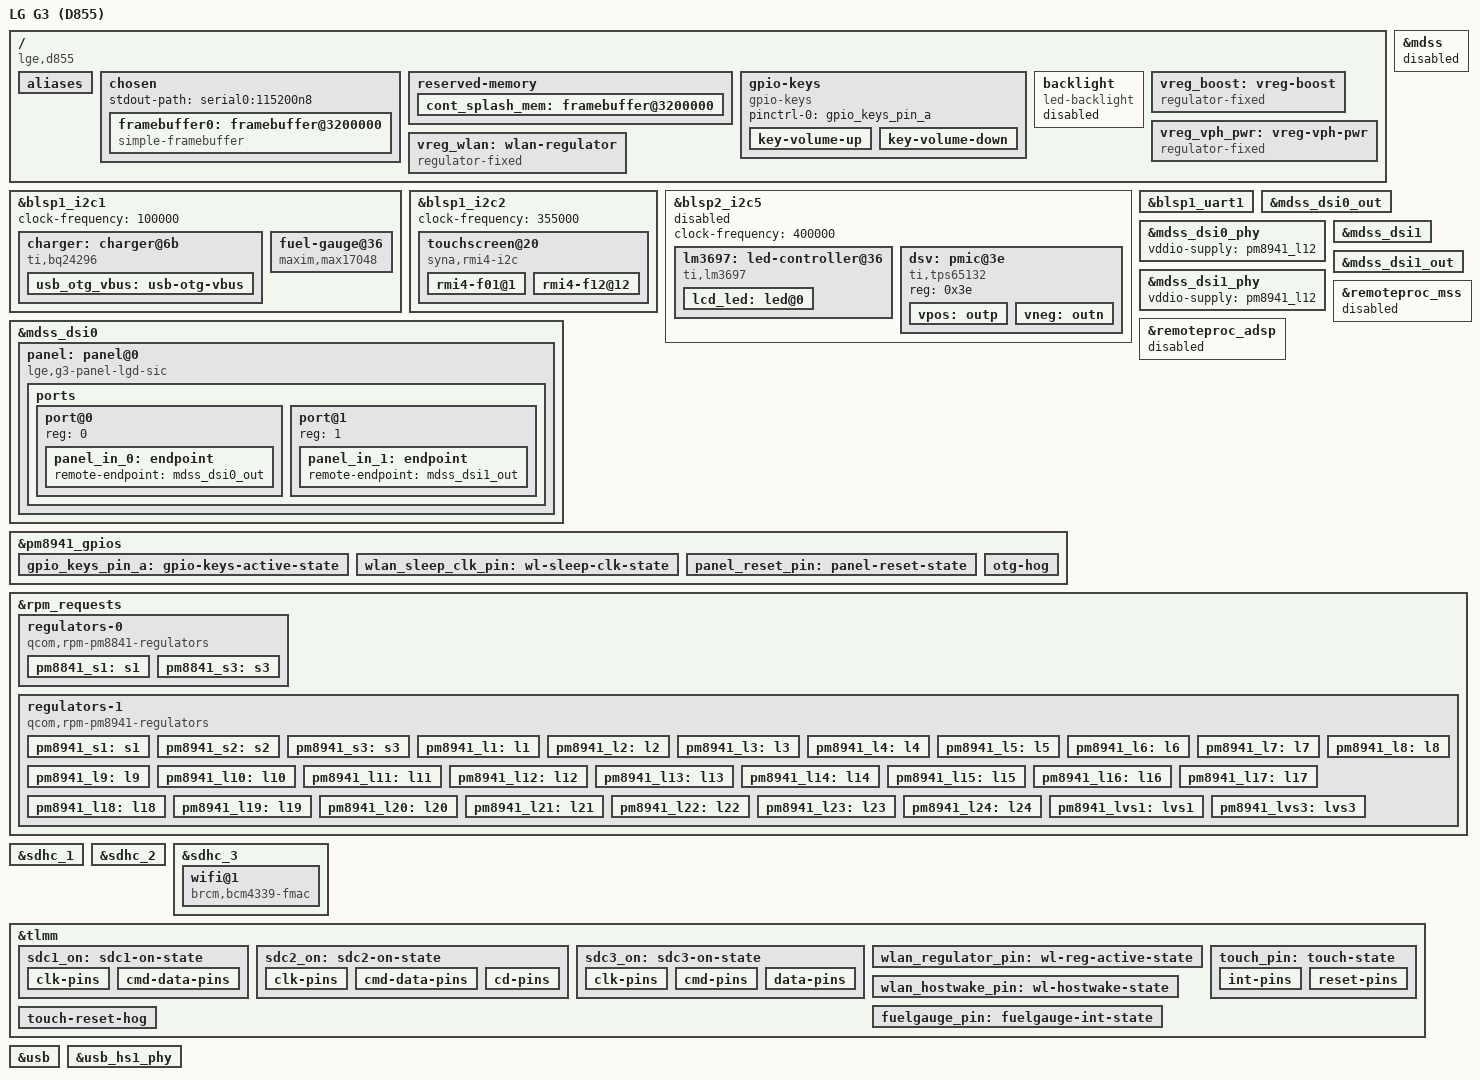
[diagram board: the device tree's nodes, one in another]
// SPDX-License-Identifier: GPL-2.0
/*
 * LG G3 (international, D855) — MSM8974AC (Snapdragon 801), PM8841 + PM8941
 *
 * Squelette de bring-up. Base : qcom-msm8974-lge-nexus5-hammerhead.dts
 * (même équipe LG, même architecture d'alimentation) et
 * qcom-msm8974pro-sony-xperia-shinano-common.dtsi (microSD sur SDHC2,
 * WiFi BCM4339 sur SDHC3).
 *
 * Câblage relevé dans le noyau downstream LineageOS (lineage-18.1) :
 *   arch/arm/boot/dts/msm8974pro-g3-global_com/
 *   arch/arm/boot/dts/msm8974pro-lge-common/
 *   arch/arm/mach-msm/lge/wifi_bcm_lge.c, 8974ac-g3/board-8974-g3-*.c
 *
 * Les éléments marqués TODO ne sont pas encore validés sur le matériel.
 */

/dts-v1/;

#include "qcom-msm8974pro.dtsi"
#include "pm8841.dtsi"
#include "pm8941.dtsi"
#include <dt-bindings/gpio/gpio.h>
#include <dt-bindings/input/input.h>
#include <dt-bindings/leds/common.h>
#include <dt-bindings/pinctrl/qcom,pmic-gpio.h>

/ {
	model = "LG G3 (D855)";
	compatible = "lge,d855", "qcom,msm8974pro", "qcom,msm8974";
	chassis-type = "handset";

	/* downstream : qcom,msm-id = <194 118 0x10001> (ancien format 3 cellules) */
	qcom,msm-id = <194 0x10001>;

	aliases {
		mmc0 = &sdhc_1;		/* eMMC */
		mmc1 = &sdhc_2;		/* microSD */
		mmc2 = &sdhc_3;		/* WiFi SDIO */
		serial0 = &blsp1_uart1;
	};

	chosen {
		#address-cells = <1>;
		#size-cells = <1>;
		ranges;

		stdout-path = "serial0:115200n8";

		/*
		 * Image laissée par le bootloader LG (relevée avec mdp-dump) :
		 * un seul tampon 1440x2560 RGB888 à 0x03200000, stride 4320,
		 * lu par les pipes RGB0 et RGB1 (une moitié de 720 par lien DSI).
		 * Linux continue simplement à y écrire (simpledrm). Les horloges
		 * et alimentations du MDP restent allumées grâce à
		 * clk_ignore_unused / pd_ignore_unused / regulator_ignore_unused,
		 * la bande passante mémoire grâce au vote d'interconnect.
		 * Si le rouge et le bleu sont inversés : format = "b8g8r8"
		 * n'existe pas, le dire et on passera par un autre format.
		 */
		framebuffer0: framebuffer@3200000 {
			compatible = "simple-framebuffer";
			reg = <0x03200000 (1440 * 2560 * 3)>;
			memory-region = <&cont_splash_mem>;
			/*
			 * Garde la bande passante MDP -> DDR (patch 0003 de
			 * simpledrm) : sans ce vote, l'interconnect la coupe et
			 * l'écran passe au bleu (underflow du MDP5).
			 */
			interconnects = <&mmssnoc MNOC_MAS_MDP_PORT0 &bimc BIMC_SLV_EBI_CH0>;
			width = <1440>;
			height = <2560>;
			stride = <(1440 * 3)>;
			format = "r8g8b8";
		};
	};

	reserved-memory {
		/* Tampon d'affichage du bootloader, à ne pas réutiliser */
		cont_splash_mem: framebuffer@3200000 {
			reg = <0x03200000 (1440 * 2560 * 3)>;
			no-map;
		};
	};

	gpio-keys {
		compatible = "gpio-keys";

		pinctrl-names = "default";
		pinctrl-0 = <&gpio_keys_pin_a>;

		key-volume-up {
			label = "volume_up";
			gpios = <&pm8941_gpios 2 GPIO_ACTIVE_LOW>;
			linux,input-type = <1>;
			linux,code = <KEY_VOLUMEUP>;
			debounce-interval = <15>;
		};

		key-volume-down {
			label = "volume_down";
			gpios = <&pm8941_gpios 3 GPIO_ACTIVE_LOW>;
			linux,input-type = <1>;
			linux,code = <KEY_VOLUMEDOWN>;
			debounce-interval = <15>;
		};
	};

	/* Le LM3697 expose une LED : led-backlight en fait un backlight pour le panel */
	backlight: backlight {
		compatible = "led-backlight";
		leds = <&lcd_led>;
		default-brightness-level = <177>;
		status = "disabled";	/* TODO : activer avec le panel */
	};

	/* Boost "bb_boost" piloté par PM8941 GPIO21 (identique au Nexus 5) */
	vreg_boost: vreg-boost {
		compatible = "regulator-fixed";

		regulator-name = "vreg-boost";
		regulator-min-microvolt = <3150000>;
		regulator-max-microvolt = <3150000>;

		regulator-always-on;
		regulator-boot-on;

		gpio = <&pm8941_gpios 21 GPIO_ACTIVE_HIGH>;
		enable-active-high;

		pinctrl-names = "default";
		pinctrl-0 = <&boost_bypass_n_pin>;
	};

	vreg_vph_pwr: vreg-vph-pwr {
		compatible = "regulator-fixed";
		regulator-name = "vph-pwr";

		regulator-min-microvolt = <3600000>;
		regulator-max-microvolt = <3600000>;

		regulator-always-on;
	};

	/* WL_REG_ON = TLMM 69 (wifi_bcm_lge.c : WLAN_POWER) */
	vreg_wlan: wlan-regulator {
		compatible = "regulator-fixed";

		regulator-name = "wl-reg";
		regulator-min-microvolt = <3300000>;
		regulator-max-microvolt = <3300000>;

		gpio = <&tlmm 69 GPIO_ACTIVE_HIGH>;
		enable-active-high;

		pinctrl-names = "default";
		pinctrl-0 = <&wlan_regulator_pin>;
	};
};

/* Chargeur bq24296 + jauge MAX17048 (même bus et mêmes IRQ que le Nexus 5) */
&blsp1_i2c1 {
	status = "okay";
	clock-frequency = <100000>;

	charger: charger@6b {
		compatible = "ti,bq24296";
		reg = <0x6b>;
		/* EXT_CHG_INT = PM8941 GPIO22 */
		interrupts-extended = <&spmi_bus 0 0xd5 0 IRQ_TYPE_EDGE_FALLING>;

		omit-battery-class;

		usb_otg_vbus: usb-otg-vbus { };
	};

	fuel-gauge@36 {
		compatible = "maxim,max17048";
		reg = <0x36>;

		/* TODO : rcomp downstream = 103 (cellule LGC) / 55 (TCD) */
		maxim,double-soc;
		maxim,rcomp = /bits/ 8 <103>;

		interrupts-extended = <&tlmm 9 IRQ_TYPE_LEVEL_LOW>;

		pinctrl-names = "default";
		pinctrl-0 = <&fuelgauge_pin>;

		maxim,alert-low-soc-level = <2>;
	};
};

/* Tactile Synaptics S3528 (RMI4, F12) */
&blsp1_i2c2 {
	status = "okay";
	clock-frequency = <355000>;

	touchscreen@20 {
		compatible = "syna,rmi4-i2c";
		reg = <0x20>;

		interrupts-extended = <&tlmm 73 IRQ_TYPE_EDGE_FALLING>;
		vdd-supply = <&pm8941_l22>;
		vio-supply = <&pm8941_lvs3>;
		/* downstream : reset_delay = 10 ms ; marge pour le démarrage */
		syna,startup-delay-ms = <100>;

		pinctrl-names = "default";
		pinctrl-0 = <&touch_pin>;

		#address-cells = <1>;
		#size-cells = <0>;

		rmi4-f01@1 {
			reg = <0x1>;
			syna,nosleep-mode = <1>;
		};

		rmi4-f12@12 {
			reg = <0x12>;
			syna,sensor-type = <1>;
		};
	};
};

/*
 * Rétroéclairage LM3697 (0x36, HWEN = TLMM 91) et alimentation panel
 * TPS65132 (0x3e, DSV_EN = TLMM 56 / 100). Désactivé tant que l'affichage
 * passe par le framebuffer du bootloader : Linux ne doit pas toucher à ces
 * alimentations (sinon écran rose, voir README).
 */
&blsp2_i2c5 {
	status = "disabled";
	clock-frequency = <400000>;

	lm3697: led-controller@36 {
		compatible = "ti,lm3697";
		reg = <0x36>;

		enable-gpios = <&tlmm 91 GPIO_ACTIVE_HIGH>;

		#address-cells = <1>;
		#size-cells = <0>;

		lcd_led: led@0 {
			reg = <0>;
			led-sources = <0 1>;	/* HVLED1 + HVLED2 (rev >= c) */
			ti,brightness-resolution = <2047>;
			label = "lcd-backlight";
		};
	};

	/* TODO : vérifier le binding et les tensions (+/-5,5 V typ.) */
	dsv: pmic@3e {
		compatible = "ti,tps65132";
		reg = <0x3e>;

		vpos: outp {
			regulator-name = "lcd-vpos";
			regulator-min-microvolt = <5500000>;
			regulator-max-microvolt = <5500000>;
			enable-gpios = <&tlmm 56 GPIO_ACTIVE_HIGH>;
		};

		vneg: outn {
			regulator-name = "lcd-vneg";
			regulator-min-microvolt = <5500000>;
			regulator-max-microvolt = <5500000>;
			enable-gpios = <&tlmm 100 GPIO_ACTIVE_HIGH>;
		};
	};
};

/* UART de debug (points de test, non câblé en externe) */
&blsp1_uart1 {
	status = "okay";
};

/*
 * TODO : Bluetooth BCM4339 sur BLSP1 UART5 (0xf9921000, GPIO 23-26),
 * reset TLMM 41, host-wake TLMM 42, dev-wake TLMM 62.
 * Le nœud UART n'existe pas encore dans qcom-msm8974.dtsi.
 */

/*
 * Affichage : panel LGD SIC 1440x2560 vidéo, en DSI couplé (« bonded ») :
 * moitié gauche sur DSI0, moitié droite sur DSI1, 720x2560 et 4 lanes
 * chacun, commandes envoyées sur les deux liens. Driver :
 * panel-lge-g3-lgd-sic (patch 0002 du paquet noyau).
 *
 * DÉSACTIVÉ : le driver MDP5 mainline (MSM8974) ne sait pas piloter deux
 * interfaces DSI couplées. Le côté DSI (qcom,dual-dsi-mode) existe, mais
 * pas le côté MDP5. Ces nœuds décrivent le matériel pour le jour où ce
 * support existera ; en attendant, l'affichage passe par le framebuffer
 * laissé par le bootloader (voir chosen/framebuffer).
 */
&mdss {
	status = "disabled";
};

&mdss_dsi0 {
	vdda-supply = <&pm8941_l2>;
	vdd-supply = <&pm8941_lvs3>;
	vddio-supply = <&pm8941_l12>;

	qcom,dual-dsi-mode;
	qcom,master-dsi;
	qcom,sync-dual-dsi;

	panel: panel@0 {
		compatible = "lge,g3-panel-lgd-sic";
		reg = <0>;

		vdd-supply = <&pm8941_l10>;
		vsp-supply = <&vpos>;
		vsn-supply = <&vneg>;
		reset-gpios = <&pm8941_gpios 19 GPIO_ACTIVE_LOW>;

		backlight = <&backlight>;

		pinctrl-names = "default";
		pinctrl-0 = <&panel_reset_pin>;

		ports {
			#address-cells = <1>;
			#size-cells = <0>;

			port@0 {
				reg = <0>;
				panel_in_0: endpoint {
					remote-endpoint = <&mdss_dsi0_out>;
				};
			};

			port@1 {
				reg = <1>;
				panel_in_1: endpoint {
					remote-endpoint = <&mdss_dsi1_out>;
				};
			};
		};
	};
};

&mdss_dsi0_out {
	remote-endpoint = <&panel_in_0>;
	data-lanes = <0 1 2 3>;
};

&mdss_dsi0_phy {
	vddio-supply = <&pm8941_l12>;
};

&mdss_dsi1 {
	vdda-supply = <&pm8941_l2>;
	vdd-supply = <&pm8941_lvs3>;
	vddio-supply = <&pm8941_l12>;

	qcom,dual-dsi-mode;
	qcom,sync-dual-dsi;

	/* En mode couplé, la PLL de DSI0 cadence les deux liens */
	assigned-clock-parents = <&mdss_dsi0_phy DSI_BYTE_PLL_CLK>,
				 <&mdss_dsi0_phy DSI_PIXEL_PLL_CLK>;
};

&mdss_dsi1_out {
	remote-endpoint = <&panel_in_1>;
	data-lanes = <0 1 2 3>;
};

&mdss_dsi1_phy {
	vddio-supply = <&pm8941_l12>;
};

&pm8941_gpios {
	gpio_keys_pin_a: gpio-keys-active-state {
		pins = "gpio2", "gpio3";
		function = "normal";

		bias-pull-up;
		power-source = <PM8941_GPIO_S3>;
	};

	wlan_sleep_clk_pin: wl-sleep-clk-state {
		pins = "gpio16";
		function = "func2";

		output-high;
		power-source = <PM8941_GPIO_S3>;
	};

	/* Reset du panel (downstream : qcom,platform-reset-gpio) */
	panel_reset_pin: panel-reset-state {
		pins = "gpio19";
		function = "normal";

		bias-disable;
		power-source = <PM8941_GPIO_S3>;
		qcom,drive-strength = <PMIC_GPIO_STRENGTH_HIGH>;
	};

	/* PM8941 GPIO35 : OTG_EN du switch OVP (comme sur le Nexus 5) */
	otg-hog {
		gpio-hog;
		gpios = <35 GPIO_ACTIVE_HIGH>;
		output-high;
		line-name = "otg-gpio";
	};
};

&remoteproc_adsp {
	/* TODO : nécessite adsp.mdt depuis la partition modem */
	status = "disabled";
};

&remoteproc_mss {
	mss-supply = <&pm8841_s3>;
	mx-supply = <&pm8841_s1>;
	pll-supply = <&pm8941_l12>;
	/* TODO : nécessite mba.mbn + modem.mdt depuis la partition modem */
	status = "disabled";
};

&rpm_requests {
	regulators-0 {
		compatible = "qcom,rpm-pm8841-regulators";

		pm8841_s1: s1 {
			regulator-min-microvolt = <675000>;
			regulator-max-microvolt = <1050000>;
		};

		pm8841_s3: s3 {
			regulator-min-microvolt = <1050000>;
			regulator-max-microvolt = <1050000>;
		};
	};

	/* Valeurs reprises du Nexus 5, TODO : comparer au downstream */
	regulators-1 {
		compatible = "qcom,rpm-pm8941-regulators";

		vdd_l1_l3-supply = <&pm8941_s1>;
		vdd_l2_lvs1_2_3-supply = <&pm8941_s3>;
		vdd_l4_l11-supply = <&pm8941_s1>;
		vdd_l5_l7-supply = <&pm8941_s2>;
		vdd_l6_l12_l14_l15-supply = <&pm8941_s2>;
		vdd_l8_l16_l18_l19-supply = <&vreg_vph_pwr>;
		vdd_l9_l10_l17_l22-supply = <&vreg_boost>;
		vdd_l13_l20_l23_l24-supply = <&vreg_boost>;
		vdd_l21-supply = <&vreg_boost>;

		pm8941_s1: s1 {
			regulator-min-microvolt = <1300000>;
			regulator-max-microvolt = <1300000>;
			regulator-always-on;
			regulator-boot-on;
		};

		pm8941_s2: s2 {
			regulator-min-microvolt = <2150000>;
			regulator-max-microvolt = <2150000>;
			regulator-boot-on;
		};

		pm8941_s3: s3 {
			regulator-min-microvolt = <1800000>;
			regulator-max-microvolt = <1800000>;
			regulator-always-on;
			regulator-boot-on;
		};

		pm8941_l1: l1 {
			regulator-min-microvolt = <1225000>;
			regulator-max-microvolt = <1225000>;
			regulator-always-on;
			regulator-boot-on;
		};

		pm8941_l2: l2 {
			regulator-min-microvolt = <1200000>;
			regulator-max-microvolt = <1200000>;
		};

		pm8941_l3: l3 {
			regulator-min-microvolt = <1225000>;
			regulator-max-microvolt = <1225000>;
		};

		pm8941_l4: l4 {
			regulator-min-microvolt = <1225000>;
			regulator-max-microvolt = <1225000>;
		};

		pm8941_l5: l5 {
			regulator-min-microvolt = <1800000>;
			regulator-max-microvolt = <1800000>;
		};

		pm8941_l6: l6 {
			regulator-min-microvolt = <1800000>;
			regulator-max-microvolt = <1800000>;
			regulator-boot-on;
		};

		pm8941_l7: l7 {
			regulator-min-microvolt = <1800000>;
			regulator-max-microvolt = <1800000>;
			regulator-boot-on;
		};

		pm8941_l8: l8 {
			regulator-min-microvolt = <1800000>;
			regulator-max-microvolt = <1800000>;
		};

		pm8941_l9: l9 {
			regulator-min-microvolt = <1800000>;
			regulator-max-microvolt = <2950000>;
		};

		pm8941_l10: l10 {
			regulator-min-microvolt = <1800000>;
			regulator-max-microvolt = <2950000>;
		};

		pm8941_l11: l11 {
			regulator-min-microvolt = <1300000>;
			regulator-max-microvolt = <1300000>;
		};

		pm8941_l12: l12 {
			regulator-min-microvolt = <1800000>;
			regulator-max-microvolt = <1800000>;
			regulator-always-on;
			regulator-boot-on;
		};

		/* microSD VQMMC (downstream : jusqu'à 22 mA) */
		pm8941_l13: l13 {
			regulator-min-microvolt = <1800000>;
			regulator-max-microvolt = <2950000>;
			regulator-system-load = <22000>;
			regulator-allow-set-load;
			regulator-boot-on;
		};

		pm8941_l14: l14 {
			regulator-min-microvolt = <1800000>;
			regulator-max-microvolt = <1800000>;
		};

		pm8941_l15: l15 {
			regulator-min-microvolt = <2050000>;
			regulator-max-microvolt = <2050000>;
		};

		pm8941_l16: l16 {
			regulator-min-microvolt = <2700000>;
			regulator-max-microvolt = <2700000>;
		};

		pm8941_l17: l17 {
			regulator-min-microvolt = <2850000>;
			regulator-max-microvolt = <2850000>;
		};

		pm8941_l18: l18 {
			regulator-min-microvolt = <2850000>;
			regulator-max-microvolt = <2850000>;
		};

		pm8941_l19: l19 {
			regulator-min-microvolt = <3000000>;
			regulator-max-microvolt = <3300000>;
		};

		/* eMMC VMMC */
		pm8941_l20: l20 {
			regulator-min-microvolt = <2950000>;
			regulator-max-microvolt = <2950000>;
			regulator-system-load = <200000>;
			regulator-allow-set-load;
			regulator-boot-on;
		};

		/*
		 * microSD VMMC (downstream : jusqu'à 800 mA). Sans vote de charge,
		 * le RPM peut laisser le LDO en mode basse consommation, trop
		 * faible pour une carte en cours d'initialisation. Même réglage
		 * que le Xperia Z3 et le Galaxy S5.
		 */
		pm8941_l21: l21 {
			regulator-min-microvolt = <2950000>;
			regulator-max-microvolt = <2950000>;
			regulator-system-load = <500000>;
			regulator-allow-set-load;
			regulator-boot-on;
		};

		/* Tactile : le downstream le fixe à 3,3 V */
		pm8941_l22: l22 {
			regulator-min-microvolt = <3300000>;
			regulator-max-microvolt = <3300000>;
		};

		pm8941_l23: l23 {
			regulator-min-microvolt = <3000000>;
			regulator-max-microvolt = <3000000>;
		};

		pm8941_l24: l24 {
			regulator-min-microvolt = <3075000>;
			regulator-max-microvolt = <3075000>;
			regulator-boot-on;
		};

		pm8941_lvs1: lvs1 {};
		pm8941_lvs3: lvs3 {};
	};
};

/* eMMC */
&sdhc_1 {
	status = "okay";

	vmmc-supply = <&pm8941_l20>;
	vqmmc-supply = <&pm8941_s3>;

	pinctrl-names = "default", "sleep";
	pinctrl-0 = <&sdc1_on>;
	pinctrl-1 = <&sdc1_off>;
};

/* microSD (rev_a1 et suivantes), détection carte TLMM 95 active basse */
&sdhc_2 {
	status = "okay";

	vmmc-supply = <&pm8941_l21>;
	vqmmc-supply = <&pm8941_l13>;

	cd-gpios = <&tlmm 95 GPIO_ACTIVE_LOW>;

	pinctrl-names = "default", "sleep";
	pinctrl-0 = <&sdc2_on>;
	pinctrl-1 = <&sdc2_off>;
};

/* WiFi BCM4339 en SDIO, host-wake TLMM 44 */
&sdhc_3 {
	status = "okay";

	max-frequency = <100000000>;
	vmmc-supply = <&vreg_wlan>;
	vqmmc-supply = <&pm8941_s3>;
	non-removable;

	pinctrl-names = "default";
	pinctrl-0 = <&sdc3_on>;

	wifi@1 {
		compatible = "brcm,bcm4339-fmac", "brcm,bcm4329-fmac";
		reg = <1>;

		brcm,drive-strength = <10>;

		interrupts-extended = <&tlmm 44 IRQ_TYPE_LEVEL_HIGH>;
		interrupt-names = "host-wake";

		pinctrl-names = "default";
		pinctrl-0 = <&wlan_sleep_clk_pin>, <&wlan_hostwake_pin>;
	};
};

&tlmm {
	sdc1_on: sdc1-on-state {
		clk-pins {
			pins = "sdc1_clk";
			drive-strength = <16>;
			bias-disable;
		};

		cmd-data-pins {
			pins = "sdc1_cmd", "sdc1_data";
			drive-strength = <10>;
			bias-pull-up;
		};
	};

	sdc2_on: sdc2-on-state {
		/*
		 * Downstream G3 : horloge réduite de 16 à 6 mA (« 16mA --> 6mA »
		 * dans qcom,pad-drv-on). À 16 mA les modes UHS échouent.
		 */
		clk-pins {
			pins = "sdc2_clk";
			drive-strength = <6>;
			bias-disable;
		};

		cmd-data-pins {
			pins = "sdc2_cmd", "sdc2_data";
			drive-strength = <10>;
			bias-pull-up;
		};

		cd-pins {
			pins = "gpio95";
			function = "gpio";
			drive-strength = <2>;
			bias-disable;
		};
	};

	sdc3_on: sdc3-on-state {
		clk-pins {
			pins = "gpio40";
			function = "sdc3";
			drive-strength = <10>;
			bias-disable;
		};

		cmd-pins {
			pins = "gpio39";
			function = "sdc3";
			drive-strength = <10>;
			bias-pull-up;
		};

		data-pins {
			pins = "gpio35", "gpio36", "gpio37", "gpio38";
			function = "sdc3";
			drive-strength = <10>;
			bias-pull-up;
		};
	};

	wlan_regulator_pin: wl-reg-active-state {
		pins = "gpio69";
		function = "gpio";
		drive-strength = <2>;
		bias-pull-down;
	};

	wlan_hostwake_pin: wl-hostwake-state {
		pins = "gpio44";
		function = "gpio";
		drive-strength = <2>;
		bias-disable;
		input-enable;
	};

	fuelgauge_pin: fuelgauge-int-state {
		pins = "gpio9";
		function = "gpio";
		drive-strength = <2>;
		bias-disable;
		input-enable;
	};

	touch_pin: touch-state {
		int-pins {
			pins = "gpio73";
			function = "gpio";
			drive-strength = <2>;
			bias-disable;
		};

		reset-pins {
			pins = "gpio8";
			function = "gpio";
			drive-strength = <2>;
			bias-disable;
		};
	};

	/*
	 * Reset du tactile (actif bas). Le driver RMI4 ne gère pas de GPIO de
	 * reset : on le maintient relâché (niveau haut), comme le downstream
	 * après la mise sous tension.
	 */
	touch-reset-hog {
		gpio-hog;
		gpios = <8 GPIO_ACTIVE_HIGH>;
		output-high;
		line-name = "touch-reset-n";
	};
};

&usb {
	status = "okay";

	phys = <&usb_hs1_phy>;
	phy-select = <&tcsr 0xb000 0>;

	extcon = <&charger>, <&usb_id>;
	vbus-supply = <&usb_otg_vbus>;

	hnp-disable;
	srp-disable;
	adp-disable;
};

&usb_hs1_phy {
	status = "okay";

	v1p8-supply = <&pm8941_l6>;
	v3p3-supply = <&pm8941_l24>;

	qcom,init-seq = /bits/ 8 <0x1 0x64>;
};
